# STMP3770 register map
Vendor: Freescale Semiconductor (NXP); Series: STMP37xx; File version: 1.0
CPU: other r0p0, little endian, no MPU, no FPU, 2 interrupt priority bits
Registers are 32-bit, read-write, reset 0x0 unless marked. A register's access mark holds for its fields unless they carry their own. Offsets are from the block's base; [hi:lo] are bit positions; {n}, {i} and the like mark numbered series.

## PINCTRL — STMP3770 PINCTRL 引脚复用与 GPIO 控制器。提供 4 组物理引脚 Bank（Bank0~Bank3）的复用选择（MUXSEL）、驱动强度（DRIVE）、上拉电阻使能（PULL）、GPIO 输出数据（DOUT）、输入数据（DIN）、输出使能（DOE）以及中断配置（PIN2IRQ/IRQEN/IRQLEVEL/IRQPOL/IRQSTAT）。每引脚通过 2 位 MUXSEL 选择 0~3 共 4 种复用功能，值 3 通常映射为 GPIO 模式。DRIVE 寄存器按引脚配置输出驱动电流档位（_MA）与 I/O 电压域（_V）。PULL0/1/2 控制对应 Bank 的上拉电阻使能，PULL3 用于 Bank3 的 Pad Keeper 禁用。DOUT/DIN/DOE 以位掩码方式控制各 Bank 的 GPIO 输出值、输入采样值与方向。中断相关寄存器以位掩码逐引脚配置中断源选择、使能、电平/边沿触发、极性及状态。CTRL 寄存器提供模块级软复位（SFTRST）、时钟门控（CLKGATE）、Bank 存在标志（PRESENT）及中断输出路由（IRQOUT）。
Base 0x80018000
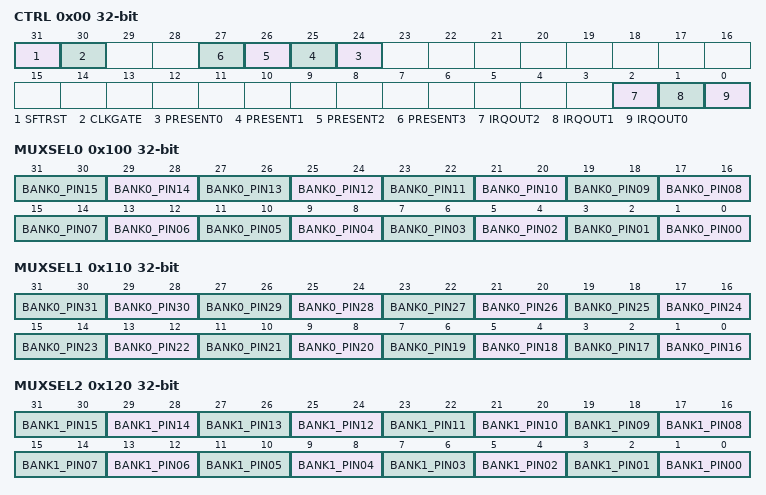
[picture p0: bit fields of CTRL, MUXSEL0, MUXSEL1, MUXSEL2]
0x00 CTRL — PINCTRL 模块控制寄存器，包含中断输出路由、Bank 存在标志、时钟门控与软复位。
  [31] SFTRST — 软复位控制，置 1 时对 PINCTRL 模块执行软复位，置 0 时正常工作。
  [30] CLKGATE — 时钟门控控制，置 1 时关闭 PINCTRL 模块时钟以节省功耗，置 0 时使能时钟。
  [n+24] PRESENT{n} (n=0..3) — Bank {n} 存在标志，只读，为 1 表示 Bank {n} 引脚在芯片中物理存在。
  [2] IRQOUT2 — Bank 2 中断输出路由使能，置 1 时将 Bank 2 的 GPIO 中断路由至 IRQ2 输出。
  [1] IRQOUT1 — Bank 1 中断输出路由使能，置 1 时将 Bank 1 的 GPIO 中断路由至 IRQ1 输出。
  [0] IRQOUT0 — Bank 0 中断输出路由使能，置 1 时将 Bank 0 的 GPIO 中断路由至 IRQ0 输出。
0x100 MUXSEL0 — Bank 0 引脚复用选择寄存器 0，配置 Pin00~Pin15 的复用功能（每引脚 2 位，0~3 对应 4 种功能，值 3 通常为 GPIO 模式）。
  [2n+1:2n] BANK0_PIN{n:02} (n=0..15) — Bank 0 引脚 {n} 的复用功能选择（2 位，0~3）。
0x110 MUXSEL1 — Bank 0 引脚复用选择寄存器 1，配置 Pin16~Pin31 的复用功能（每引脚 2 位，0~3 对应 4 种功能，值 3 通常为 GPIO 模式）。
  [2n-31:2n-32] BANK0_PIN{n} (n=16..31) — Bank 0 引脚 {n} 的复用功能选择（2 位，0~3）。
0x120 MUXSEL2 — Bank 1 引脚复用选择寄存器 2，配置 Pin00~Pin15 的复用功能（每引脚 2 位，0~3 对应 4 种功能，值 3 通常为 GPIO 模式）。
  [2n+1:2n] BANK1_PIN{n:02} (n=0..15) — Bank 1 引脚 {n} 的复用功能选择（2 位，0~3）。
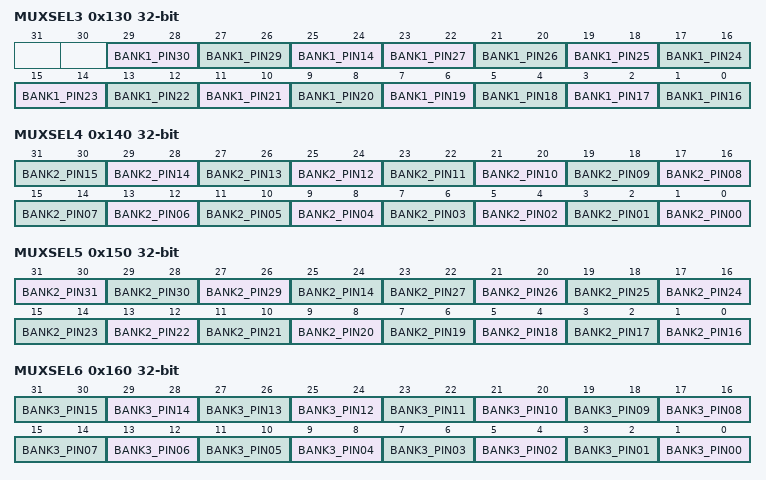
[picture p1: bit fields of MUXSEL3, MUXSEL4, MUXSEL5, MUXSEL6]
0x130 MUXSEL3 — Bank 1 引脚复用选择寄存器 3，配置 Pin16~Pin27 及 Pin14/Pin29/Pin30 的复用功能（每引脚 2 位，0~3 对应 4 种功能，值 3 通常为 GPIO 模式）。
  [29:28] BANK1_PIN30 — Bank 1 引脚 30 的复用功能选择（2 位，0~3）。
  [27:26] BANK1_PIN29 — Bank 1 引脚 29 的复用功能选择（2 位，0~3）。
  [25:24] BANK1_PIN14 — Bank 1 引脚 14 的复用功能选择（2 位，0~3）。
  [2n-31:2n-32] BANK1_PIN{n} (n=16..27) — Bank 1 引脚 {n} 的复用功能选择（2 位，0~3）。
0x140 MUXSEL4 — Bank 2 引脚复用选择寄存器 4，配置 Pin00~Pin15 的复用功能（每引脚 2 位，0~3 对应 4 种功能，值 3 通常为 GPIO 模式）。
  [2n+1:2n] BANK2_PIN{n:02} (n=0..15) — Bank 2 引脚 {n} 的复用功能选择（2 位，0~3）。
0x150 MUXSEL5 — Bank 2 引脚复用选择寄存器 5，配置 Pin16~Pin27 及 Pin14/Pin29/Pin30/Pin31 的复用功能（每引脚 2 位，0~3 对应 4 种功能，值 3 通常为 GPIO 模式）。
  [31:30] BANK2_PIN31 — Bank 2 引脚 31 的复用功能选择（2 位，0~3）。
  [29:28] BANK2_PIN30 — Bank 2 引脚 30 的复用功能选择（2 位，0~3）。
  [27:26] BANK2_PIN29 — Bank 2 引脚 29 的复用功能选择（2 位，0~3）。
  [25:24] BANK2_PIN14 — Bank 2 引脚 14 的复用功能选择（2 位，0~3）。
  [2n-31:2n-32] BANK2_PIN{n} (n=16..27) — Bank 2 引脚 {n} 的复用功能选择（2 位，0~3）。
0x160 MUXSEL6 — Bank 3 引脚复用选择寄存器 6，配置 Pin00~Pin15 的复用功能（每引脚 2 位，0~3 对应 4 种功能，值 3 通常为 GPIO 模式）。
  [2n+1:2n] BANK3_PIN{n:02} (n=0..15) — Bank 3 引脚 {n} 的复用功能选择（2 位，0~3）。
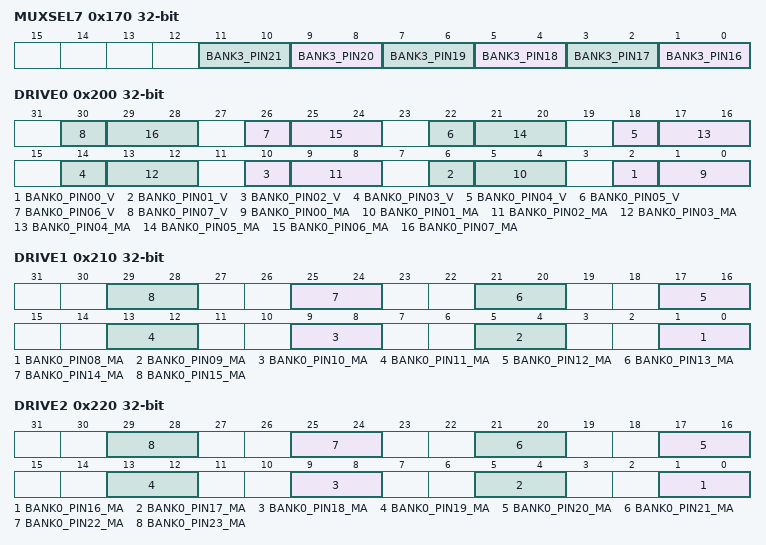
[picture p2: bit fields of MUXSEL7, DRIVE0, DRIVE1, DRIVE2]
0x170 MUXSEL7 — Bank 3 引脚复用选择寄存器 7，配置 Pin16~Pin21 的复用功能（每引脚 2 位，0~3 对应 4 种功能，值 3 通常为 GPIO 模式）。
  [2n-31:2n-32] BANK3_PIN{n} (n=16..21) — Bank 3 引脚 {n} 的复用功能选择（2 位，0~3）。
0x200 DRIVE0 — Bank 0 驱动强度与电压寄存器 0，配置 Pin00~Pin07 的输出驱动电流档位（_MA，2 位）与 I/O 电压域选择（_V，1 位）。
  [4n+2] BANK0_PIN{n:02}_V (n=0..7) — Bank 0 引脚 {n} 的 I/O 电压域选择（1 位）。
  [4n+1:4n] BANK0_PIN{n:02}_MA (n=0..7) — Bank 0 引脚 {n} 的输出驱动电流档位选择（2 位）。
0x210 DRIVE1 — Bank 0 驱动强度寄存器 1，配置 Pin08~Pin15 的输出驱动电流档位（_MA，2 位，无 _V 字段）。
  [4n-31:4n-32] BANK0_PIN{n:02}_MA (n=8..15) — Bank 0 引脚 {n} 的输出驱动电流档位选择（2 位）。
0x220 DRIVE2 — Bank 0 驱动强度寄存器 2，配置 Pin16~Pin23 的输出驱动电流档位（_MA，2 位，无 _V 字段）。
  [4n-63:4n-64] BANK0_PIN{n}_MA (n=16..23) — Bank 0 引脚 {n} 的输出驱动电流档位选择（2 位）。
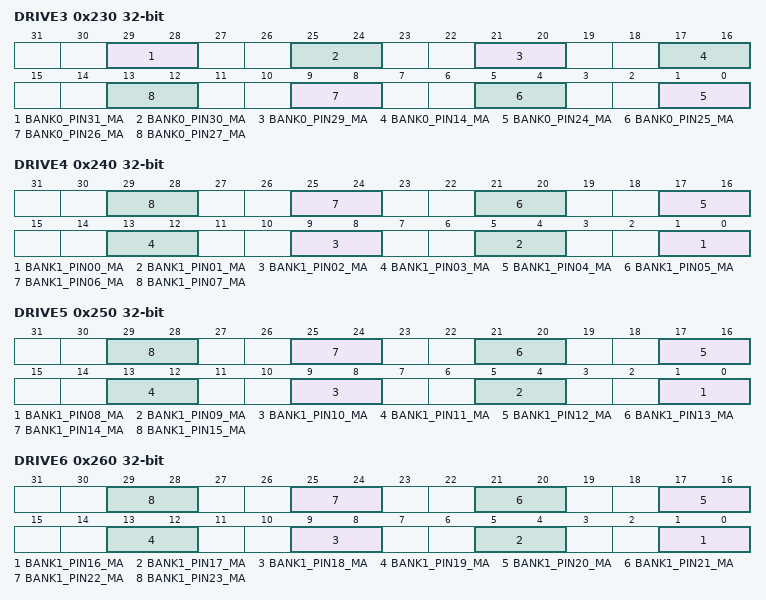
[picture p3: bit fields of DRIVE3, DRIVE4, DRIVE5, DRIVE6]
0x230 DRIVE3 — Bank 0 驱动强度寄存器 3，配置 Pin24~Pin27 及 Pin14/Pin29/Pin30/Pin31 的输出驱动电流档位（_MA，2 位，无 _V 字段）。
  [29:28] BANK0_PIN31_MA — Bank 0 引脚 31 的输出驱动电流档位选择（2 位）。
  [25:24] BANK0_PIN30_MA — Bank 0 引脚 30 的输出驱动电流档位选择（2 位）。
  [21:20] BANK0_PIN29_MA — Bank 0 引脚 29 的输出驱动电流档位选择（2 位）。
  [17:16] BANK0_PIN14_MA — Bank 0 引脚 14 的输出驱动电流档位选择（2 位）。
  [4n-95:4n-96] BANK0_PIN{n}_MA (n=24..27) — Bank 0 引脚 {n} 的输出驱动电流档位选择（2 位）。
0x240 DRIVE4 — Bank 1 驱动强度寄存器 4，配置 Pin00~Pin07 的输出驱动电流档位（_MA，2 位，无 _V 字段）。
  [4n+1:4n] BANK1_PIN{n:02}_MA (n=0..7) — Bank 1 引脚 {n} 的输出驱动电流档位选择（2 位）。
0x250 DRIVE5 — Bank 1 驱动强度寄存器 5，配置 Pin08~Pin15 的输出驱动电流档位（_MA，2 位，无 _V 字段）。
  [4n-31:4n-32] BANK1_PIN{n:02}_MA (n=8..15) — Bank 1 引脚 {n} 的输出驱动电流档位选择（2 位）。
0x260 DRIVE6 — Bank 1 驱动强度寄存器 6，配置 Pin16~Pin23 的输出驱动电流档位（_MA，2 位，无 _V 字段）。
  [4n-63:4n-64] BANK1_PIN{n}_MA (n=16..23) — Bank 1 引脚 {n} 的输出驱动电流档位选择（2 位）。
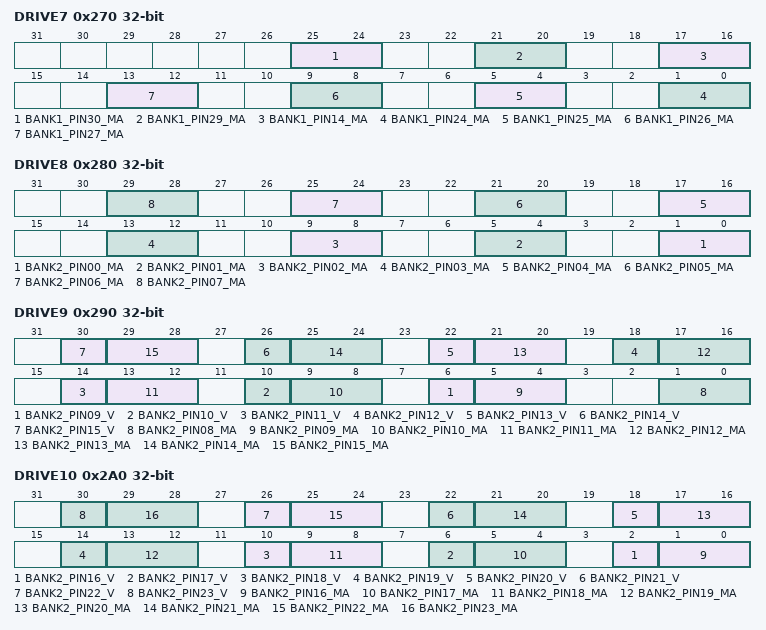
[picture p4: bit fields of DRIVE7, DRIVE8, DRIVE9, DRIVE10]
0x270 DRIVE7 — Bank 1 驱动强度寄存器 7，配置 Pin24~Pin27 及 Pin14/Pin29/Pin30 的输出驱动电流档位（_MA，2 位，无 _V 字段）。
  [25:24] BANK1_PIN30_MA — Bank 1 引脚 30 的输出驱动电流档位选择（2 位）。
  [21:20] BANK1_PIN29_MA — Bank 1 引脚 29 的输出驱动电流档位选择（2 位）。
  [17:16] BANK1_PIN14_MA — Bank 1 引脚 14 的输出驱动电流档位选择（2 位）。
  [4n-95:4n-96] BANK1_PIN{n}_MA (n=24..27) — Bank 1 引脚 {n} 的输出驱动电流档位选择（2 位）。
0x280 DRIVE8 — Bank 2 驱动强度寄存器 8，配置 Pin00~Pin07 的输出驱动电流档位（_MA，2 位，无 _V 字段）。
  [4n+1:4n] BANK2_PIN{n:02}_MA (n=0..7) — Bank 2 引脚 {n} 的输出驱动电流档位选择（2 位）。
0x290 DRIVE9 — Bank 2 驱动强度与电压寄存器 9，配置 Pin08~Pin15 的输出驱动电流档位（_MA，2 位）与电压域（_V，1 位）；其中 Pin08 仅有 _MA 无 _V。
  [4n-30] BANK2_PIN{n:02}_V (n=9..15) — Bank 2 引脚 {n} 的 I/O 电压域选择（1 位）。
  [4n-31:4n-32] BANK2_PIN{n:02}_MA (n=8..15) — Bank 2 引脚 {n} 的输出驱动电流档位选择（2 位）。
0x2A0 DRIVE10 — Bank 2 驱动强度与电压寄存器 10，配置 Pin16~Pin23 的输出驱动电流档位（_MA，2 位）与电压域（_V，1 位）。
  [4n-62] BANK2_PIN{n}_V (n=16..23) — Bank 2 引脚 {n} 的 I/O 电压域选择（1 位）。
  [4n-63:4n-64] BANK2_PIN{n}_MA (n=16..23) — Bank 2 引脚 {n} 的输出驱动电流档位选择（2 位）。
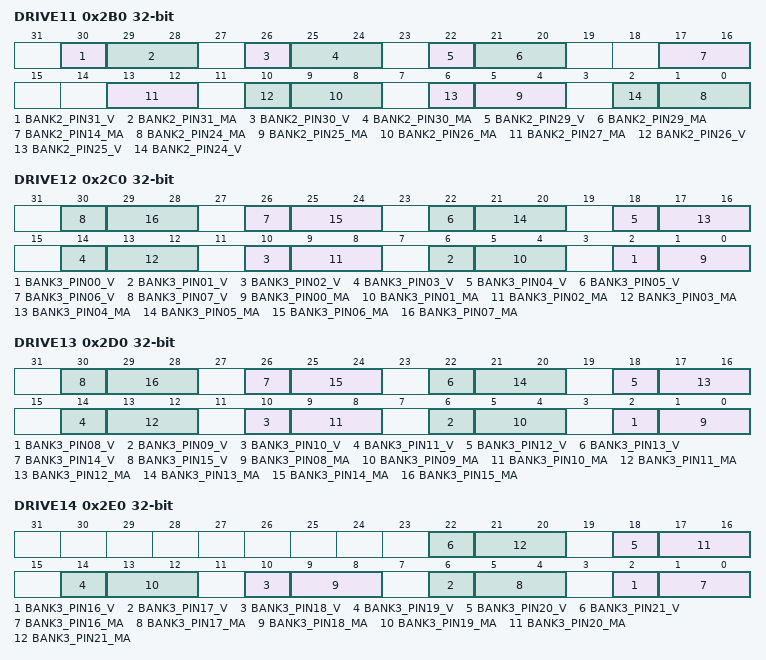
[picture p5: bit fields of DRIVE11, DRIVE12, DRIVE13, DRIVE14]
0x2B0 DRIVE11 — Bank 2 驱动强度与电压寄存器 11，配置 Pin24~Pin26、Pin14、Pin29~Pin31 的输出驱动电流档位（_MA，2 位）与电压域（_V，1 位）；其中 Pin27 仅有 _MA 无 _V。
  [30] BANK2_PIN31_V — Bank 2 引脚 31 的 I/O 电压域选择（1 位）。
  [29:28] BANK2_PIN31_MA — Bank 2 引脚 31 的输出驱动电流档位选择（2 位）。
  [26] BANK2_PIN30_V — Bank 2 引脚 30 的 I/O 电压域选择（1 位）。
  [25:24] BANK2_PIN30_MA — Bank 2 引脚 30 的输出驱动电流档位选择（2 位）。
  [22] BANK2_PIN29_V — Bank 2 引脚 29 的 I/O 电压域选择（1 位）。
  [21:20] BANK2_PIN29_MA — Bank 2 引脚 29 的输出驱动电流档位选择（2 位）。
  [17:16] BANK2_PIN14_MA — Bank 2 引脚 14 的输出驱动电流档位选择（2 位）。
  [4n-95:4n-96] BANK2_PIN{n}_MA (n=24..27) — Bank 2 引脚 {n} 的输出驱动电流档位选择（2 位）。
  [10] BANK2_PIN26_V — Bank 2 引脚 26 的 I/O 电压域选择（1 位）。
  [6] BANK2_PIN25_V — Bank 2 引脚 25 的 I/O 电压域选择（1 位）。
  [2] BANK2_PIN24_V — Bank 2 引脚 24 的 I/O 电压域选择（1 位）。
0x2C0 DRIVE12 — Bank 3 驱动强度与电压寄存器 12，配置 Pin00~Pin07 的输出驱动电流档位（_MA，2 位）与电压域（_V，1 位）。
  [4n+2] BANK3_PIN{n:02}_V (n=0..7) — Bank 3 引脚 {n} 的 I/O 电压域选择（1 位）。
  [4n+1:4n] BANK3_PIN{n:02}_MA (n=0..7) — Bank 3 引脚 {n} 的输出驱动电流档位选择（2 位）。
0x2D0 DRIVE13 — Bank 3 驱动强度与电压寄存器 13，配置 Pin08~Pin15 的输出驱动电流档位（_MA，2 位）与电压域（_V，1 位）。
  [4n-30] BANK3_PIN{n:02}_V (n=8..15) — Bank 3 引脚 {n} 的 I/O 电压域选择（1 位）。
  [4n-31:4n-32] BANK3_PIN{n:02}_MA (n=8..15) — Bank 3 引脚 {n} 的输出驱动电流档位选择（2 位）。
0x2E0 DRIVE14 — Bank 3 驱动强度与电压寄存器 14，配置 Pin16~Pin21 的输出驱动电流档位（_MA，2 位）与电压域（_V，1 位）。
  [4n-62] BANK3_PIN{n}_V (n=16..21) — Bank 3 引脚 {n} 的 I/O 电压域选择（1 位）。
  [4n-63:4n-64] BANK3_PIN{n}_MA (n=16..21) — Bank 3 引脚 {n} 的输出驱动电流档位选择（2 位）。
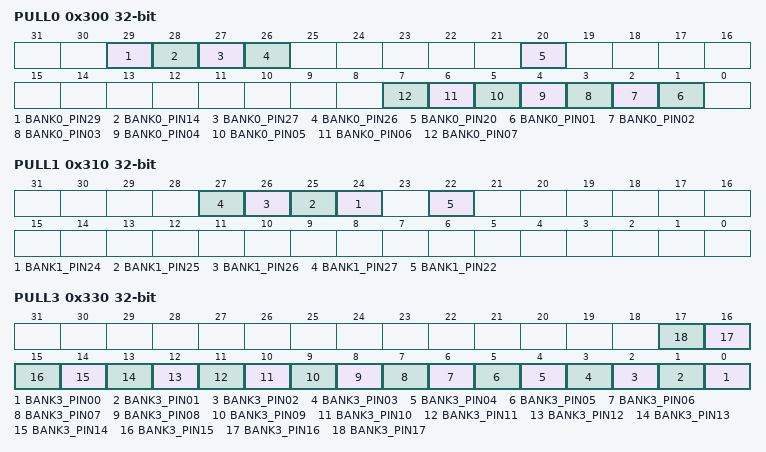
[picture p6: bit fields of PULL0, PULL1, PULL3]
0x300 PULL0 — Bank 0 上拉电阻使能寄存器，逐位控制对应引脚的上拉电阻使能（1 表示使能内部上拉电阻）。
  [29] BANK0_PIN29 — Bank 0 引脚 29 的上拉电阻使能控制（1 使能）。
  [28] BANK0_PIN14 — Bank 0 引脚 14 的上拉电阻使能控制（1 使能）。
  [27] BANK0_PIN27 — Bank 0 引脚 27 的上拉电阻使能控制（1 使能）。
  [26] BANK0_PIN26 — Bank 0 引脚 26 的上拉电阻使能控制（1 使能）。
  [20] BANK0_PIN20 — Bank 0 引脚 20 的上拉电阻使能控制（1 使能）。
  [n] BANK0_PIN{n:02} (n=1..7) — Bank 0 引脚 {n} 的上拉电阻使能控制（1 使能）。
0x310 PULL1 — Bank 1 上拉电阻使能寄存器，逐位控制对应引脚的上拉电阻使能（1 表示使能内部上拉电阻）。
  [n] BANK1_PIN{n} (n=24..27) — Bank 1 引脚 {n} 的上拉电阻使能控制（1 使能）。
  [22] BANK1_PIN22 — Bank 1 引脚 22 的上拉电阻使能控制（1 使能）。
0x320 PULL2 — Bank 2 上拉电阻使能寄存器，逐位控制对应引脚的上拉电阻使能（1 表示使能内部上拉电阻）。
  [14] BANK2_PIN14 — Bank 2 引脚 14 的上拉电阻使能控制（1 使能）。
0x330 PULL3 — Bank 3 Pad Keeper 禁用寄存器，逐位控制对应引脚的 Pad Keeper 功能禁用（1 表示禁用 Pad Keeper）。
  [n] BANK3_PIN{n:02} (n=0..17) — Bank 3 引脚 {n} 的 Pad Keeper 禁用控制（1 禁用）。
0x400 DOUT0 — Bank 0 GPIO 数据输出寄存器，低 30 位逐位控制对应引脚的 GPIO 输出电平（1 高电平，0 低电平）。
  [29:0] DOUT — Bank 0 的 GPIO 输出数据位域（30 位），逐位对应引脚 0~29 的输出电平。
0x410 DOUT1 — Bank 1 GPIO 数据输出寄存器，低 29 位逐位控制对应引脚的 GPIO 输出电平（1 高电平，0 低电平）。
  [28:0] DOUT — Bank 1 的 GPIO 输出数据位域（29 位），逐位对应引脚 0~28 的输出电平。
0x420 DOUT2 — Bank 2 GPIO 数据输出寄存器，32 位逐位控制对应引脚的 GPIO 输出电平（1 高电平，0 低电平）。
  [31:0] DOUT — Bank 2 的 GPIO 输出数据位域（32 位），逐位对应引脚 0~31 的输出电平。
0x500 DIN0 — Bank 0 GPIO 数据输入寄存器，低 30 位反映对应引脚的当前输入采样电平（只读）。
  [29:0] DIN — Bank 0 的 GPIO 输入数据位域（30 位），逐位反映引脚 0~29 的当前输入电平。
0x510 DIN1 — Bank 1 GPIO 数据输入寄存器，低 29 位反映对应引脚的当前输入采样电平（只读）。
  [28:0] DIN — Bank 1 的 GPIO 输入数据位域（29 位），逐位反映引脚 0~28 的当前输入电平。
0x520 DIN2 — Bank 2 GPIO 数据输入寄存器，32 位反映对应引脚的当前输入采样电平（只读）。
  [31:0] DIN — Bank 2 的 GPIO 输入数据位域（32 位），逐位反映引脚 0~31 的当前输入电平。
0x600 DOE0 — Bank 0 GPIO 输出使能寄存器，低 30 位逐位控制对应引脚的方向（1 输出模式，0 输入/高阻模式）。
  [29:0] DOE — Bank 0 的 GPIO 输出使能位域（30 位），逐位控制引脚 0~29 的方向。
0x610 DOE1 — Bank 1 GPIO 输出使能寄存器，低 29 位逐位控制对应引脚的方向（1 输出模式，0 输入/高阻模式）。
  [28:0] DOE — Bank 1 的 GPIO 输出使能位域（29 位），逐位控制引脚 0~28 的方向。
0x620 DOE2 — Bank 2 GPIO 输出使能寄存器，32 位逐位控制对应引脚的方向（1 输出模式，0 输入/高阻模式）。
  [31:0] DOE — Bank 2 的 GPIO 输出使能位域（32 位），逐位控制引脚 0~31 的方向。
0x700 PIN2IRQ0 — Bank 0 中断源选择寄存器，32 位逐位将对应引脚映射为中断源（1 表示该引脚可产生中断）。
  [31:0] PIN2IRQ — Bank 0 的引脚中断源选择位域（32 位），逐位使能引脚 0~31 作为中断源。
0x710 PIN2IRQ1 — Bank 1 中断源选择寄存器，低 31 位逐位将对应引脚映射为中断源（1 表示该引脚可产生中断）。
  [30:0] PIN2IRQ — Bank 1 的引脚中断源选择位域（31 位），逐位使能引脚 0~30 作为中断源。
0x720 PIN2IRQ2 — Bank 2 中断源选择寄存器，32 位逐位将对应引脚映射为中断源（1 表示该引脚可产生中断）。
  [31:0] PIN2IRQ — Bank 2 的引脚中断源选择位域（32 位），逐位使能引脚 0~31 作为中断源。
0x800 IRQEN0 — Bank 0 中断使能寄存器，32 位逐位控制对应引脚中断的使能（1 允许中断，0 屏蔽中断）。
  [31:0] IRQEN — Bank 0 的中断使能位域（32 位），逐位控制引脚 0~31 的中断屏蔽。
0x810 IRQEN1 — Bank 1 中断使能寄存器，低 31 位逐位控制对应引脚中断的使能（1 允许中断，0 屏蔽中断）。
  [30:0] IRQEN — Bank 1 的中断使能位域（31 位），逐位控制引脚 0~30 的中断屏蔽。
0x820 IRQEN2 — Bank 2 中断使能寄存器，32 位逐位控制对应引脚中断的使能（1 允许中断，0 屏蔽中断）。
  [31:0] IRQEN — Bank 2 的中断使能位域（32 位），逐位控制引脚 0~31 的中断屏蔽。
0x900 IRQLEVEL0 — Bank 0 中断电平/边沿触发寄存器，32 位逐位配置对应引脚的中断触发方式（1 电平触发，0 边沿触发）。
  [31:0] IRQLEVEL — Bank 0 的中断触发方式位域（32 位），逐位配置引脚 0~31 为电平触发（1）或边沿触发（0）。
0x910 IRQLEVEL1 — Bank 1 中断电平/边沿触发寄存器，低 31 位逐位配置对应引脚的中断触发方式（1 电平触发，0 边沿触发）。
  [30:0] IRQLEVEL — Bank 1 的中断触发方式位域（31 位），逐位配置引脚 0~30 为电平触发（1）或边沿触发（0）。
0x920 IRQLEVEL2 — Bank 2 中断电平/边沿触发寄存器，32 位逐位配置对应引脚的中断触发方式（1 电平触发，0 边沿触发）。
  [31:0] IRQLEVEL — Bank 2 的中断触发方式位域（32 位），逐位配置引脚 0~31 为电平触发（1）或边沿触发（0）。
0xA00 IRQPOL0 — Bank 0 中断极性寄存器，32 位逐位配置对应引脚的中断触发极性（1 高电平/上升沿有效，0 低电平/下降沿有效）。
  [31:0] IRQPOL — Bank 0 的中断极性位域（32 位），逐位配置引脚 0~31 的触发极性。
0xA10 IRQPOL1 — Bank 1 中断极性寄存器，低 31 位逐位配置对应引脚的中断触发极性（1 高电平/上升沿有效，0 低电平/下降沿有效）。
  [30:0] IRQPOL — Bank 1 的中断极性位域（31 位），逐位配置引脚 0~30 的触发极性。
0xA20 IRQPOL2 — Bank 2 中断极性寄存器，32 位逐位配置对应引脚的中断触发极性（1 高电平/上升沿有效，0 低电平/下降沿有效）。
  [31:0] IRQPOL — Bank 2 的中断极性位域（32 位），逐位配置引脚 0~31 的触发极性。
0xB00 IRQSTAT0 — Bank 0 中断状态寄存器，32 位逐位反映对应引脚的中断挂起状态（1 表示有中断待处理，写 1 清除）。
  [31:0] IRQSTAT — Bank 0 的中断状态位域（32 位），逐位反映引脚 0~31 的中断挂起状态。
0xB10 IRQSTAT1 — Bank 1 中断状态寄存器，低 31 位逐位反映对应引脚的中断挂起状态（1 表示有中断待处理，写 1 清除）。
  [30:0] IRQSTAT — Bank 1 的中断状态位域（31 位），逐位反映引脚 0~30 的中断挂起状态。
0xB20 IRQSTAT2 — Bank 2 中断状态寄存器，32 位逐位反映对应引脚的中断挂起状态（1 表示有中断待处理，写 1 清除）。
  [31:0] IRQSTAT — Bank 2 的中断状态位域（32 位），逐位反映引脚 0~31 的中断挂起状态。
